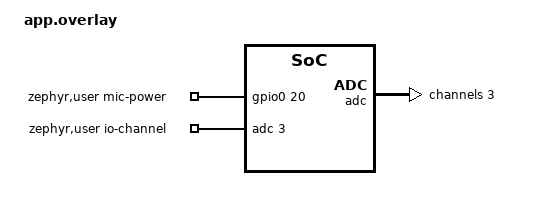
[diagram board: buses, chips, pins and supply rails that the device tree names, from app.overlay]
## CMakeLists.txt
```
# Freestanding Zephyr application: ZEPHYR_BASE must point at the Zephyr repo
# inside ~/zephyrproject.

cmake_minimum_required(VERSION 3.20.0)

find_package(Zephyr REQUIRED HINTS $ENV{ZEPHYR_BASE})
project(microbit_v2_zephyr)

target_sources(app PRIVATE
  src/main.c
  src/accel.c
  src/audio.c
  src/ble.c
  src/buttons.c
  src/display.c
  src/temp.c
)
```

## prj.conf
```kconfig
CONFIG_LOG=y
CONFIG_MAIN_STACK_SIZE=2048

# --- console shell -----------------------------------------------------------
# The board already chooses uart0 for both `zephyr,console` and
# `zephyr,shell-uart`, so the shell lands on the same USB CDC port the log
# already uses. SHELL_LOG_BACKEND is `default y if LOG`, which is what keeps log
# records from shredding a half-typed command line, so it is not set here.
CONFIG_SHELL=y
# Deferred logging moves formatting off the calling thread. The sensor threads
# log from timer and input callbacks, where the synchronous mode's spinlock is
# held across the whole UART write.
CONFIG_LOG_MODE_DEFERRED=y
# `log enable dbg accel` at runtime, which is the point of the per-module
# LOG_MODULE_REGISTER calls -- accel.c, temp.c, and buttons.c all have LOG_DBG
# statements that nothing could otherwise reach without a rebuild.
#
# This only works because every module now registers at LOG_LEVEL_DBG. That
# argument is the COMPILE-TIME ceiling, and log_filter_set() clamps the runtime
# level to it, so with the modules at LOG_LEVEL_INF `log enable dbg accel`
# answered "level set to inf" and silently did nothing.
CONFIG_LOG_CMDS=y
# Raising that ceiling is what makes the console noisy if this line is missing.
# The serial backend's initial limit defaults to LOG_LEVEL_DEFAULT, "the system
# limit", which follows the compile ceiling -- so every module came up at dbg
# and temp.c alone printed a die reading every second. This pins the *initial
# runtime* level to inf. It is not a second ceiling: log_filter_set() clamps
# against the compile-time level, so `log enable dbg accel` still reaches dbg.
CONFIG_SHELL_BACKEND_SERIAL_LOG_LEVEL_INF=y
# `sensor get accel0` and `adc adc@40007000 read 3` reach the LSM303AGR and the
# microphone channel independently of the app's own threads, which is what makes
# them useful for telling a driver fault from an application one.
#
# SENSOR_SHELL is the most expensive line in this file: it `select`s
# SENSOR_ASYNC_API, which pulls in RTIO, and measures at 14 KB of flash and
# 6.6 KB of RAM -- more RAM than the whole rest of the shell tier. Drop it first
# if this ever needs to shrink; ADC_SHELL costs almost nothing by comparison.
CONFIG_SENSOR_SHELL=y
CONFIG_ADC_SHELL=y
# `input report 1 30 1` injects a synthetic button-A press. buttons.c registers
# its callback with INPUT_CALLBACK_DEFINE(NULL, ...), so it listens to every
# device and cannot tell a synthetic event from a real one -- the whole path
# runs, BLE notification included. That is the acoustically clean way to start a
# capture: pressing A physically taps the PCB centimetres from the microphone
# and puts the thump into the very block being measured. `input dump on` logs
# every event, which is the cheapest way to watch the button stream.
CONFIG_INPUT_SHELL=y
CONFIG_INPUT_EVENT_DUMP=y
# KERNEL_SHELL and DEVICE_SHELL are both `default y` once SHELL is on. These two
# are what `kernel thread stacks` needs to report high-water marks, and they are
# only `imply`-ed, so state them: every stack size in this app is a guess until
# it has been measured.
CONFIG_INIT_STACKS=y
CONFIG_THREAD_NAME=y
# `audio raw` and `audio spectrum` print floats. SENSOR_SHELL selects this too,
# but src/audio.c should not depend on that having happened.
CONFIG_CBPRINTF_FP_SUPPORT=y

# --- sensors -----------------------------------------------------------------
# CONFIG_SENSOR is enough: TEMP_NRF5 and LIS2DH are both `default y` off their
# devicetree nodes.
CONFIG_SENSOR=y
# No trigger: the app polls. P0.25 is COMBINED_SENSOR_INT, an open-collector line
# with no pull-up anywhere on the board, and Zephyr's board DTS omits GPIO_PULL_UP,
# so the line can never rise once something has pulled it low. It is also shared
# with the magnetometer and the interface MCU. Selecting NONE drops the driver's
# trigger thread and its 1 KB stack. See accel.c.
CONFIG_LIS2DH_TRIGGER_NONE=y
CONFIG_LIS2DH_ACCEL_RANGE_2G=y
# The magnetometer is unused here, and leaving it out is not just dead weight:
# LIS2MDL is `default y` off the board's DTS and its trigger mode defaults to
# GLOBAL_THREAD, which arms a rising-edge interrupt on that same never-rising
# P0.25 at init, for a sensor nothing reads.
CONFIG_LIS2MDL=n

# --- buttons and buzzer ------------------------------------------------------
CONFIG_GPIO=y
CONFIG_INPUT=y
CONFIG_BUZZER=y

# --- LED matrix --------------------------------------------------------------
# MICROBIT_DISPLAY has no `default y` and depends on DISPLAY + PRINTK.
CONFIG_DISPLAY=y
CONFIG_MICROBIT_DISPLAY=y

# --- audio capture and FFT ---------------------------------------------------
CONFIG_ADC=y
CONFIG_FPU=y
CONFIG_CMSIS_DSP=y
CONFIG_CMSIS_DSP_TRANSFORM=y
CONFIG_CMSIS_DSP_STATISTICS=y
CONFIG_CMSIS_DSP_WINDOW=y

# --- bluetooth ---------------------------------------------------------------
CONFIG_BT=y
CONFIG_BT_PERIPHERAL=y
CONFIG_BT_DEVICE_NAME="microbit-v2"

# The default ATT MTU is 23, which leaves 20 usable bytes -- three accelerometer
# samples. Raising it is what makes the batching requirement mean anything.
CONFIG_BT_L2CAP_TX_MTU=247
CONFIG_BT_BUF_ACL_TX_SIZE=251
CONFIG_BT_BUF_ACL_RX_SIZE=251
CONFIG_BT_CTLR_DATA_LENGTH_MAX=251

# No CONFIG_BT_GATT_CLIENT: this is a pure GATT server. It was set so the
# peripheral could call bt_gatt_exchange_mtu() itself, which turned out to hang
# the ATT transaction against BlueZ and drop the link 30 s later. See ble.c.

# Ask for a short connection interval: 6 * 1.25 ms = 7.5 ms to 12 * 1.25 = 15 ms.
CONFIG_BT_PERIPHERAL_PREF_MIN_INT=6
CONFIG_BT_PERIPHERAL_PREF_MAX_INT=12
CONFIG_BT_PERIPHERAL_PREF_LATENCY=0
CONFIG_BT_PERIPHERAL_PREF_TIMEOUT=400
```

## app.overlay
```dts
/*
 * The micro:bit V2's microphone is an ANALOG MEMS part. Zephyr's board files
 * describe it not at all, so everything about it lives here:
 *
 *   - signal out -> P0.05 = AIN3
 *   - enable/LED -> P0.20
 *
 * These pin numbers come from the micro:bit hardware documentation, not from
 * Zephyr. The SoC dtsi leaves `adc` disabled, so we enable it too.
 */

/ {
	zephyr,user {
		io-channels = <&adc 3>;
		mic-power-gpios = <&gpio0 20 GPIO_ACTIVE_HIGH>;
	};
};

&adc {
	status = "okay";
	#address-cells = <1>;
	#size-cells = <0>;

	channel@3 {
		reg = <3>;
		/* Full scale is 0.6 V / 4 = 150 mV, which is chosen for the
		 * microphone rather than for safety. The obvious setting --
		 * ADC_GAIN_1_4 against ADC_REF_VDD_1_4, full scale VDD -- put
		 * the whole signal in the bottom 2 % of the range, where what
		 * the FFT mostly saw was the ADC's own quantisation: a 1 kHz
		 * tone stood 4.0 dB clear of the noise floor there against
		 * 18.6 dB here. The microphone idles near 69 mV, so 150 mV
		 * leaves the bias at about 46 % of range with ~29 dB of
		 * headroom before clipping -- watch `audio raw`'s "at rails"
		 * counter if a loud source is ever held against the board.
		 * Measured; see README.md, "known limitations".
		 */
		zephyr,gain = "ADC_GAIN_4";
		zephyr,reference = "ADC_REF_INTERNAL";
		/* The reference itself, 0.6 V -- not the full-scale input.
		 * adc_raw_to_millivolts() multiplies by this and then inverts
		 * the x4 gain, which lands full scale at 150 mV. Nothing in the
		 * capture path reads it, but without it
		 * `adc_raw_to_millivolts_dt()` silently converts everything to
		 * 0 mV: adc_dt_spec fills vref_mv with DT_PROP_OR(..., 0), so
		 * the omission costs a wrong answer rather than a build error.
		 * `audio raw` and the `adc` shell command are the users.
		 */
		zephyr,vref-mv = <600>;
		zephyr,acquisition-time = <ADC_ACQ_TIME(ADC_ACQ_TIME_MICROSECONDS, 3)>;
		zephyr,input-positive = <NRF_SAADC_AIN3>;	/* P0.05 */
		zephyr,resolution = <12>;
	};
};
```

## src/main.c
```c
/*
 * See README.md for the requirements this implements and for the hardware
 * notes -- in particular, why the microphone goes through the SAADC.
 */

#include "accel.h"
#include "audio.h"
#include "ble.h"
#include "buttons.h"
#include "display.h"
#include "temp.h"

#include <zephyr/kernel.h>
#include <zephyr/logging/log.h>

LOG_MODULE_REGISTER(main, LOG_LEVEL_DBG);

/* How often to report queue health on the console. */
#define STATS_PERIOD_MS 10000

int main(void)
{
	int err;

	LOG_INF("micro:bit V2 sensor application starting");

	err = display_init();
	if (err) {
		return err;
	}

	err = buttons_init();
	if (err) {
		return err;
	}

	err = audio_start();
	if (err) {
		return err;
	}

	err = ble_start();
	if (err) {
		return err;
	}

	err = accel_start();
	if (err) {
		return err;
	}

	err = temp_start();
	if (err) {
		return err;
	}

	display_text("hi");

	for (;;) {
		k_sleep(K_MSEC(STATS_PERIOD_MS));
		LOG_INF("accel queue %u/%u, dropped %u, overruns %u",
			k_msgq_num_used_get(&accel_msgq),
			k_msgq_num_free_get(&accel_msgq) + k_msgq_num_used_get(&accel_msgq),
			accel_dropped(), accel_overruns());
	}

	return 0;
}
```

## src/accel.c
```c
/*
 * LSM303AGR accelerometer at 100 Hz.
 *
 * This polls on a kernel timer rather than using the chip's data-ready
 * interrupt. The board makes the trigger unusable as Zephyr describes it, but
 * not for the reason the polarity of the pin suggests.
 *
 * On the V2 schematic the sensor's INT1_XL drives the base of T7, a DTC143E
 * digital NPN, whose collector is COMBINED_SENSOR_INT on P0.25. (The
 * magnetometer's DRDY drives T5 onto the same net, as does the interface MCU.)
 * That common-emitter stage inverts, so the chip's default ACTIVE-HIGH INT1 is
 * already the right polarity here -- the board is what makes the line
 * active-low and open-collector, and the LSM303AGR's own polarity bit should be
 * left alone.
 *
 * What is missing is a pull-up. Nothing on the board pulls this net high, and
 * Zephyr's board DTS declares irq-gpios without GPIO_PULL_UP, so lis2dh's bare
 * gpio_pin_configure_dt(..., GPIO_INPUT) leaves the pin floating. The first
 * data-ready pulls it to 0 V, the read releases T7, and the floating input just
 * stays there: measured, P0.25 sits low forever and no further edge occurs.
 * Polarity is provably not the blocker -- int1-gpio-config defaults to
 * EDGE_BOTH, which would have caught an edge in either direction.
 *
 * An overlay setting GPIO_PULL_UP on the accel's irq-gpios (plus
 * int1-gpio-config = LEVEL_LOW) would make the trigger work. Polling is kept
 * anyway because the line is shared: the interface MCU can assert it while the
 * accelerometer is idle, and hold it low across our own edges. A 6-byte burst
 * at 100 Hz is ~2 % of a 400 kHz I2C bus. See README.md, "known limitations".
 */

#include "accel.h"

#include <zephyr/device.h>
#include <zephyr/drivers/sensor.h>
#include <zephyr/logging/log.h>

LOG_MODULE_REGISTER(accel, LOG_LEVEL_DBG);

#define ACCEL_SAMPLE_RATE_HZ 100
#define ACCEL_PERIOD_MS      (1000 / ACCEL_SAMPLE_RATE_HZ)

/* One second of headroom. The BLE thread drains far faster than this when a
 * central is subscribed; the depth only matters while nobody is listening.
 */
#define ACCEL_QUEUE_DEPTH 128

#define ACCEL_STACK_SIZE 1024
#define ACCEL_PRIORITY   5

K_MSGQ_DEFINE(accel_msgq, sizeof(struct accel_sample), ACCEL_QUEUE_DEPTH, 4);

static const struct device *const accel_dev = DEVICE_DT_GET(DT_ALIAS(accel0));
static K_TIMER_DEFINE(accel_timer, NULL, NULL);
static uint32_t dropped;
static uint32_t overruns;

/* The sensor API reports m/s^2. Convert via micro-m/s^2 so the whole thing stays
 * in integer arithmetic: 1 g = 9.80665 m/s^2.
 */
static int16_t to_milli_g(const struct sensor_value *val)
{
	int64_t micro_m_s2 = sensor_value_to_micro(val);

	return (int16_t)CLAMP((micro_m_s2 * 1000) / 9806650, INT16_MIN, INT16_MAX);
}

static void sample_once(void)
{
	struct sensor_value val[3];
	struct accel_sample sample;
	int err;

	err = sensor_sample_fetch_chan(accel_dev, SENSOR_CHAN_ACCEL_XYZ);
	if (err == -ENODATA) {
		/* The chip had no new sample: its data-ready bit was still clear. Normal
		 * for a poller -- it happens on the first read after the ODR change, and
		 * whenever our 10 ms tick drifts just ahead of the sensor's own clock.
		 */
		LOG_DBG("no new sample");
		return;
	}
	if (err) {
		LOG_ERR("fetch failed (%d)", err);
		return;
	}

	err = sensor_channel_get(accel_dev, SENSOR_CHAN_ACCEL_XYZ, val);
	if (err) {
		LOG_ERR("channel get failed (%d)", err);
		return;
	}

	sample.t_ms = k_uptime_get_32();
	sample.x = to_milli_g(&val[0]);
	sample.y = to_milli_g(&val[1]);
	sample.z = to_milli_g(&val[2]);

	/* Drop the oldest sample rather than the newest: a stalled consumer should
	 * cost us history, not the live signal.
	 */
	if (k_msgq_put(&accel_msgq, &sample, K_NO_WAIT) != 0) {
		struct accel_sample discard;

		(void)k_msgq_get(&accel_msgq, &discard, K_NO_WAIT);
		(void)k_msgq_put(&accel_msgq, &sample, K_NO_WAIT);
		dropped++;
	}
}

static void accel_thread(void *p1, void *p2, void *p3)
{
	ARG_UNUSED(p1);
	ARG_UNUSED(p2);
	ARG_UNUSED(p3);

	k_timer_start(&accel_timer, K_MSEC(ACCEL_PERIOD_MS), K_MSEC(ACCEL_PERIOD_MS));

	for (;;) {
		/* Counts every expiry, so the period stays anchored to the timer
		 * instead of drifting by however long each read takes.
		 */
		uint32_t ticks = k_timer_status_sync(&accel_timer);

		if (ticks > 1) {
			overruns += ticks - 1;
		}

		sample_once();
	}
}

K_THREAD_DEFINE(accel_tid, ACCEL_STACK_SIZE, accel_thread, NULL, NULL, NULL, ACCEL_PRIORITY, 0,
		K_TICKS_FOREVER);

int accel_start(void)
{
	struct sensor_value odr = {.val1 = ACCEL_SAMPLE_RATE_HZ, .val2 = 0};
	int err;

	if (!device_is_ready(accel_dev)) {
		LOG_ERR("%s not ready", accel_dev->name);
		return -ENODEV;
	}

	/* Match the chip's output rate to the poll rate, so each read returns a
	 * fresh sample rather than repeating one.
	 */
	err = sensor_attr_set(accel_dev, SENSOR_CHAN_ACCEL_XYZ, SENSOR_ATTR_SAMPLING_FREQUENCY,
			      &odr);
	if (err) {
		LOG_ERR("cannot set %d Hz ODR (%d)", ACCEL_SAMPLE_RATE_HZ, err);
		return err;
	}

	k_thread_start(accel_tid);
	LOG_INF("accelerometer polling at %d Hz", ACCEL_SAMPLE_RATE_HZ);
	return 0;
}

uint32_t accel_dropped(void)
{
	return dropped;
}

uint32_t accel_overruns(void)
{
	return overruns;
}
```

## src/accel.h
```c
#ifndef APP_ACCEL_H_
#define APP_ACCEL_H_

#include <stdint.h>
#include <zephyr/kernel.h>

/** One accelerometer sample. Axes are milli-g. */
struct accel_sample {
	uint32_t t_ms;
	int16_t x;
	int16_t y;
	int16_t z;
};

/** Pending samples, filled by the sampling thread, drained by the BLE thread. */
extern struct k_msgq accel_msgq;

/** Start the 100 Hz sampling thread. */
int accel_start(void);

/** Samples dropped since boot because the queue was full. */
uint32_t accel_dropped(void);

/** Sampling periods missed since boot because a read overran its 10 ms slot. */
uint32_t accel_overruns(void);

#endif /* APP_ACCEL_H_ */
```

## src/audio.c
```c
/*
 * Audio capture and peak-frequency detection.
 *
 * The micro:bit V2's microphone is an ANALOG MEMS part on AIN3, so this goes
 * through the SAADC, not the PDM peripheral. Three conditions have to hold for
 * the SAADC's hardware sample timer to engage (see start_read() in
 * drivers/adc/adc_nrfx_saadc.c): exactly one active channel, a NULL sequence
 * callback, and interval_us <= 128. Miss any of them and the driver quietly
 * falls back to software-timed sampling, which cannot hold this rate.
 *
 * One second of audio is 61 KB, so capture is block-wise: one 2048-sample read,
 * one FFT, accumulate, discard, repeat. Averaging the 15 spectra (Welch's
 * method) is what pulls a tone out of the noise floor.
 */

#include "audio.h"
#include "display.h"

#include <arm_math.h>

#include <float.h>
#include <math.h>
#include <string.h>

#include <zephyr/devicetree.h>
#include <zephyr/drivers/adc.h>
#include <zephyr/drivers/clock_control.h>
#include <zephyr/drivers/clock_control/nrf_clock_control.h>
#include <zephyr/drivers/gpio.h>
#include <zephyr/kernel.h>
#include <zephyr/logging/log.h>

#ifdef CONFIG_SHELL
#include <zephyr/shell/shell.h>
#include <zephyr/shell/shell_string_conv.h>
#endif

LOG_MODULE_REGISTER(audio, LOG_LEVEL_DBG);

#define FFT_SIZE 2048
#define FFT_BINS (FFT_SIZE / 2)

/* interval_us is an integer, and 32 us is the closest step to 32 kHz. It does
 * NOT give 1000000/32 = 31250 Hz, which is what this used to assume.
 *
 * Zephyr programs the SAADC's sample timer through interval_to_cc()
 * (drivers/adc/adc_nrfx_saadc.c:503), which returns interval_us * 16 - 1, so
 * 32 us asks for CC = 511 rather than 512. The nRF52833 then samples at
 * 16 MHz / CC. The difference is only 0.2 %, but it is a systematic bias on
 * every frequency this reports, so it is worth deriving rather than assuming --
 * measured against a tone on a known bin centre, see README.md.
 *
 * These three must move together: SAMPLE_INTERVAL_US is the only real knob.
 */
#define SAMPLE_INTERVAL_US 32
#define SAMPLE_RATE_CC     (SAMPLE_INTERVAL_US * 16 - 1) /* 511 */
#define SAMPLE_RATE_HZ     (16000000 / SAMPLE_RATE_CC)   /* 31311 */

/* 15 * 2048 / 31311 = 0.98 s. */
#define BLOCK_COUNT 15

/* Time for the microphone bias to settle after power is applied. */
#define MIC_SETTLE_MS 10

/* What a capture should take if the SAADC's hardware sample timer engaged. The
 * FFTs run between adc_read() calls, so the real figure sits a few per cent
 * above this; several times this means the driver fell back to software timing.
 */
#define CAPTURE_EXPECTED_MS ((BLOCK_COUNT * FFT_SIZE * 1000U) / SAMPLE_RATE_HZ + MIC_SETTLE_MS)

/* Ignore DC and the bins below roughly 30 Hz. Bin width is 15.29 Hz. */
#define MIN_BIN 2

#define AUDIO_STACK_SIZE 2048
#define AUDIO_PRIORITY   6

static const struct adc_dt_spec mic_adc = ADC_DT_SPEC_GET(DT_PATH(zephyr_user));
static const struct gpio_dt_spec mic_power =
	GPIO_DT_SPEC_GET(DT_PATH(zephyr_user), mic_power_gpios);

/* The SAADC's SAMPLERATE.CC timer counts PCLK16M, which derives from HFCLK --
 * and HFCLK runs from the internal RC oscillator unless something asks for the
 * crystal. The BLE controller asks around each radio event
 * (z_nrf_clock_bt_ctlr_hf_request) and drops it again, so without this a capture
 * is stitched together from crystal-accurate and RC-accurate stretches and the
 * reported frequency lands about 0.5 % low.
 *
 * Held on by default, for the roughly one second a capture lasts. That is a real
 * cost -- the crystal draws more than the RC -- but captures are user-triggered
 * and infrequent, and BLE is starting the same crystal every few tens of
 * milliseconds anyway. `audio hfxo off` turns it back off, which is how the
 * measurement in README.md was made.
 *
 * Take it with the reference-counted request API and NOT with
 * clock_control_on()/clock_control_off(). The two are not interchangeable here:
 * clock_control_nrf_common.c tags the clock with the context that started it,
 * COMMON_CTX_API for clock_control_on() against COMMON_CTX_ONOFF for a request,
 * and set_starting_state() fails with -EPERM when a second context asks while
 * the first holds it. The nRF die-temperature driver takes HFCLK through the
 * request API for every conversion (temp_nrf5_sample_fetch, which triggers the
 * TEMP START task from the request's completion callback), so with
 * clock_control_on() the once-a-second fetch that landed inside a capture got
 * -EPERM, and that failed transition leaves the onoff manager latched in its
 * error state for good: every later request returns -EIO without ever notifying,
 * and the driver's k_sem_take(&data->device_sync_sem, K_FOREVER) never returns.
 * One capture was enough to hang the temperature thread until the next reset --
 * the die-temperature BLE stream simply stopped. The request API shares the
 * clock instead of seizing it, which is what both users need.
 */
static const struct device *const hfclk = DEVICE_DT_GET_ONE(nordic_nrf_clock_hfclk);
static atomic_t hfxo_hold = ATOMIC_INIT(1);

/* The crystal's own startup_time_us is 360, so this is only a deadlock guard. */
#define HFXO_START_TIMEOUT_MS 10

static int16_t raw[FFT_SIZE];
static float32_t fft_in[FFT_SIZE];
static float32_t fft_out[FFT_SIZE];
static float32_t window[FFT_SIZE];
static float32_t mag_avg[FFT_BINS];

static arm_rfft_fast_instance_f32 fft;

static K_SEM_DEFINE(capture_req, 0, 1);
static atomic_t capture_active;

/* Enough of the last capture to describe it on the shell. raw[] and mag_avg[]
 * survive between captures precisely so they can be inspected afterwards; these
 * say which capture they belong to and whether it ran at the right rate.
 */
static uint32_t capture_count;
static uint32_t capture_ms;

void audio_request_capture(void)
{
	if (atomic_get(&capture_active)) {
		return;
	}

	k_sem_give(&capture_req);
}

bool audio_capture_active(void)
{
	return atomic_get(&capture_active) != 0;
}

/* One 2048-sample block into raw[]. */
static int capture_block(void)
{
	static const struct adc_sequence_options opts = {
		.interval_us = SAMPLE_INTERVAL_US,
		.extra_samplings = FFT_SIZE - 1,
		/* Must stay NULL: a callback forces software-timed sampling. */
		.callback = NULL,
	};
	struct adc_sequence seq = {
		.options = &opts,
		.buffer = raw,
		.buffer_size = sizeof(raw),
	};
	int err;

	err = adc_sequence_init_dt(&mic_adc, &seq);
	if (err) {
		return err;
	}

	return adc_read_dt(&mic_adc, &seq);
}

/* Convert, remove DC, window, transform, and fold the magnitude spectrum into
 * the running average.
 */
static void accumulate_block(void)
{
	float32_t mean;

	for (size_t i = 0; i < FFT_SIZE; i++) {
		fft_in[i] = (float32_t)raw[i];
	}

	arm_mean_f32(fft_in, FFT_SIZE, &mean);
	arm_offset_f32(fft_in, -mean, fft_in, FFT_SIZE);
	arm_mult_f32(fft_in, window, fft_in, FFT_SIZE);

	/* Destroys fft_in, which is why the conversion above rebuilds it. */
	arm_rfft_fast_f32(&fft, fft_in, fft_out, 0);

	/* arm_rfft_fast_f32 packs DC in [0] and Nyquist in [1], then interleaved
	 * complex pairs. So bin k, for k >= 1, starts at fft_out[2k].
	 */
	mag_avg[0] += fabsf(fft_out[0]);
	for (size_t k = 1; k < FFT_BINS; k++) {
		float32_t re = fft_out[2 * k];
		float32_t im = fft_out[2 * k + 1];

		mag_avg[k] += sqrtf(re * re + im * im);
	}
}

/* Centre frequency of bin k. Takes a float because the peak is interpolated to
 * a fractional bin; bin_hz(1.0f) is the bin width.
 */
static float32_t bin_hz(float32_t k)
{
	return k * (float32_t)SAMPLE_RATE_HZ / (float32_t)FFT_SIZE;
}

/* Peak bin, refined by fitting a parabola through the log-magnitudes of the
 * peak and its two neighbours. Raw bin width is 15.29 Hz; this gets well inside
 * that. Returns Hz, or 0 if the spectrum has no usable peak.
 */
static float32_t peak_frequency(void)
{
	float32_t best = 0.0f;
	uint32_t peak = 0;
	float32_t a, b, c, denom, delta;

	for (uint32_t k = MIN_BIN; k < FFT_BINS - 1; k++) {
		if (mag_avg[k] > best) {
			best = mag_avg[k];
			peak = k;
		}
	}

	if (peak == 0 || best <= 0.0f) {
		return 0.0f;
	}

	a = logf(mag_avg[peak - 1] + FLT_MIN);
	b = logf(mag_avg[peak] + FLT_MIN);
	c = logf(mag_avg[peak + 1] + FLT_MIN);

	denom = a - 2.0f * b + c;
	delta = (denom != 0.0f) ? (0.5f * (a - c) / denom) : 0.0f;

	/* A parabola fitted to a genuine peak puts the vertex inside the bin. */
	if (delta < -0.5f || delta > 0.5f) {
		delta = 0.0f;
	}

	return bin_hz((float32_t)peak + delta);
}

static void run_capture(void)
{
	float32_t hz;
	uint32_t started;
	bool hold;
	int err;

	memset(mag_avg, 0, sizeof(mag_avg));

	/* Taken before the clock is read, so the crystal's ramp-up does not land
	 * in the elapsed figure the sample-rate check depends on.
	 */
	hold = atomic_get(&hfxo_hold) != 0;
	if (hold) {
		err = nrf_clock_control_request_sync(hfclk, NULL, K_MSEC(HFXO_START_TIMEOUT_MS));
		if (err) {
			LOG_WRN("cannot hold HFXO (%d)", err);
			hold = false;
		}
	}

	started = k_uptime_get_32();

	err = gpio_pin_set_dt(&mic_power, 1);
	if (err) {
		LOG_ERR("cannot power the microphone (%d)", err);
		goto release;
	}
	k_sleep(K_MSEC(MIC_SETTLE_MS));

	for (int i = 0; i < BLOCK_COUNT; i++) {
		err = capture_block();
		if (err) {
			LOG_ERR("block %d failed (%d)", i, err);
			(void)gpio_pin_set_dt(&mic_power, 0);
			goto release;
		}
		accumulate_block();
	}

	(void)gpio_pin_set_dt(&mic_power, 0);
	if (hold) {
		(void)nrf_clock_control_release(hfclk, NULL);
		hold = false;
	}

	/* Sanity check on the sample clock. The SAADC silently falls back to
	 * software-timed sampling if any precondition slips, so a capture that
	 * takes much longer than BLOCK_COUNT * FFT_SIZE / SAMPLE_RATE_HZ means the
	 * hardware timer did not engage and the reported frequency is wrong.
	 */
	capture_ms = k_uptime_get_32() - started;
	capture_count++;
	LOG_INF("capture #%u took %u ms (expected ~%u)", capture_count, capture_ms,
		CAPTURE_EXPECTED_MS);

	hz = peak_frequency();
	if (hz <= 0.0f) {
		LOG_WRN("no peak found");
		display_text("?");
		return;
	}

	LOG_INF("peak frequency %u Hz", (uint32_t)(hz + 0.5f));
	display_frequency((uint32_t)(hz + 0.5f));
	return;

release:
	if (hold) {
		(void)nrf_clock_control_release(hfclk, NULL);
	}
}

static void audio_thread(void *p1, void *p2, void *p3)
{
	ARG_UNUSED(p1);
	ARG_UNUSED(p2);
	ARG_UNUSED(p3);

	for (;;) {
		k_sem_take(&capture_req, K_FOREVER);

		atomic_set(&capture_active, 1);
		run_capture();
		atomic_set(&capture_active, 0);
	}
}

K_THREAD_DEFINE(audio_tid, AUDIO_STACK_SIZE, audio_thread, NULL, NULL, NULL, AUDIO_PRIORITY, 0,
		K_TICKS_FOREVER);

int audio_start(void)
{
	int err;

	if (!adc_is_ready_dt(&mic_adc)) {
		LOG_ERR("ADC not ready");
		return -ENODEV;
	}

	if (!gpio_is_ready_dt(&mic_power)) {
		LOG_ERR("microphone power GPIO not ready");
		return -ENODEV;
	}

	if (!device_is_ready(hfclk)) {
		LOG_ERR("HFCLK not ready");
		return -ENODEV;
	}

	err = gpio_pin_configure_dt(&mic_power, GPIO_OUTPUT_INACTIVE);
	if (err) {
		LOG_ERR("cannot configure microphone power (%d)", err);
		return err;
	}

	err = adc_channel_setup_dt(&mic_adc);
	if (err) {
		LOG_ERR("cannot set up ADC channel (%d)", err);
		return err;
	}

	/* Use the size-specific initialiser: arm_rfft_fast_init_f32() dispatches
	 * on length and drags every twiddle table from 32 to 4096 into flash.
	 */
	if (arm_rfft_fast_init_2048_f32(&fft) != ARM_MATH_SUCCESS) {
		LOG_ERR("FFT init failed");
		return -EINVAL;
	}

	arm_hanning_f32(window, FFT_SIZE);

	k_thread_start(audio_tid);
	LOG_INF("audio ready: %d Hz, %d x %d-point FFT", SAMPLE_RATE_HZ, BLOCK_COUNT, FFT_SIZE);
	return 0;
}

#ifdef CONFIG_SHELL

/* Shell diagnostics for the capture path.
 *
 * The pipeline is otherwise write-only: accumulate_block() builds a 1024-bin
 * averaged spectrum and peak_frequency() collapses it to the single number that
 * reaches the LED matrix. When that number is wrong, the spectrum and the last
 * raw block are what say why -- a harmonic picked over the fundamental, a
 * clipped or unpowered microphone, a sample clock that fell back to software
 * timing. Both buffers are static and outlive the capture, so these commands
 * only have to read them.
 *
 * Both refuse to read while the audio thread is mid-capture, which is the only
 * writer. The check is a plain load rather than a lock: these are human-driven
 * commands and the alternative -- holding a mutex across a one-second capture --
 * buys nothing here.
 */

#define SPECTRUM_ROWS_DEFAULT 8
#define SPECTRUM_ROWS_MAX     32

/* Common preamble: refuse unless there is a settled capture to describe. */
static int check_capture(const struct shell *sh)
{
	if (atomic_get(&capture_active)) {
		shell_warn(sh, "capture in progress, try again in a second");
		return -EBUSY;
	}

	if (capture_count == 0) {
		shell_warn(sh, "no capture yet -- press button A");
		return -ENODATA;
	}

	return 0;
}

/* Statistics over the last 2048-sample block, in ADC counts and in millivolts.
 *
 * The channel is single-ended with ADC_GAIN_4 against ADC_REF_INTERNAL, so
 * full scale is 150 mV across the 12-bit range and a healthy analog microphone
 * idles around 46 % of range. A mean near zero means mic-power-gpios never
 * asserted; samples resting on either rail mean the signal is clipping.
 */
static int cmd_audio_raw(const struct shell *sh, size_t argc, char **argv)
{
	const int32_t full_scale = BIT(mic_adc.resolution) - 1;
	int32_t min = INT32_MAX;
	int32_t max = INT32_MIN;
	int64_t sum = 0;
	uint32_t at_low = 0;
	uint32_t at_high = 0;
	float32_t mean, sq = 0.0f, rms;
	int32_t mean_mv, pp_mv;
	int err;

	ARG_UNUSED(argc);
	ARG_UNUSED(argv);

	err = check_capture(sh);
	if (err) {
		return err;
	}

	for (size_t i = 0; i < FFT_SIZE; i++) {
		int32_t v = raw[i];

		min = MIN(min, v);
		max = MAX(max, v);
		sum += v;
		at_low += (v <= 0);
		at_high += (v >= full_scale);
	}

	mean = (float32_t)sum / (float32_t)FFT_SIZE;

	/* AC RMS: the DC bias is most of the signal, and it is what
	 * accumulate_block() subtracts before windowing.
	 */
	for (size_t i = 0; i < FFT_SIZE; i++) {
		float32_t d = (float32_t)raw[i] - mean;

		sq += d * d;
	}
	rms = sqrtf(sq / (float32_t)FFT_SIZE);

	/* adc_raw_to_millivolts_dt() converts in place and applies the gain,
	 * reference, and resolution from the devicetree channel -- the values
	 * app.overlay compiled in, not whatever the channel is set to now. The
	 * `adc` shell command reconfigures this same channel, so after using it
	 * to retune the gain, the counts here stay true and the millivolts do
	 * not. See README.md.
	 */
	mean_mv = (int32_t)(mean + 0.5f);
	pp_mv = max - min;
	if (adc_raw_to_millivolts_dt(&mic_adc, &mean_mv) != 0 ||
	    adc_raw_to_millivolts_dt(&mic_adc, &pp_mv) != 0) {
		mean_mv = -1;
		pp_mv = -1;
	}

	shell_print(sh, "capture #%u, block %d of %d, %u ms elapsed (expected ~%u)", capture_count,
		    BLOCK_COUNT, BLOCK_COUNT, capture_ms, CAPTURE_EXPECTED_MS);
	shell_print(sh, "%d samples at %d Hz, full scale %d counts", FFT_SIZE, SAMPLE_RATE_HZ,
		    full_scale);
	shell_print(sh, "  min %6d   max %6d   peak-to-peak %6d (%d mV)", min, max, max - min,
		    pp_mv);
	shell_print(sh, "  mean %11.1f counts (%d mV)   ac rms %.1f counts", (double)mean, mean_mv,
		    (double)rms);
	shell_print(sh, "  at rails: %u low, %u high", at_low, at_high);

	return 0;
}

/* The loudest bins of the averaged spectrum, strongest first.
 *
 * Rows are selected by repeated scan rather than by sorting mag_avg[]: the
 * array is 1024 floats that the next capture wants intact, and at most 32 rows
 * a scan apiece is far cheaper than a copy. Ordering is on (magnitude, bin) so
 * that bins of exactly equal magnitude still emerge one per row instead of the
 * lowest one repeating.
 */
static int cmd_audio_spectrum(const struct shell *sh, size_t argc, char **argv)
{
	uint32_t rows = SPECTRUM_ROWS_DEFAULT;
	float32_t prev_mag = FLT_MAX;
	uint32_t prev_bin = 0;
	float32_t top = 0.0f;
	float32_t floor_mag;
	int err;

	if (argc == 2) {
		/* shell_strtol() writes *err only when the conversion fails, so
		 * this has to start at 0 -- left uninitialised it rejects every
		 * valid argument on whatever the stack happened to hold.
		 */
		long n;

		err = 0;
		n = shell_strtol(argv[1], 10, &err);

		if (err != 0 || n < 1 || n > SPECTRUM_ROWS_MAX) {
			shell_error(sh, "rows must be 1..%d", SPECTRUM_ROWS_MAX);
			return -EINVAL;
		}
		rows = (uint32_t)n;
	}

	err = check_capture(sh);
	if (err) {
		return err;
	}

	/* Over the same bins peak_frequency() searches, so the ratio between a
	 * row and this is what says whether a peak stands out at all.
	 */
	arm_mean_f32(&mag_avg[MIN_BIN], FFT_BINS - MIN_BIN, &floor_mag);

	shell_print(sh, "capture #%u, %d blocks averaged, %u ms elapsed (expected ~%u)",
		    capture_count, BLOCK_COUNT, capture_ms, CAPTURE_EXPECTED_MS);
	shell_print(sh, "%d-point fft at %d Hz, bin width %.2f Hz, bins %d..%d searched", FFT_SIZE,
		    SAMPLE_RATE_HZ, (double)bin_hz(1.0f), MIN_BIN, FFT_BINS - 2);
	shell_print(sh, "interpolated peak %.2f Hz, mean magnitude %.1f", (double)peak_frequency(),
		    (double)floor_mag);
	shell_print(sh, " rank   bin        Hz     magnitude      dBc");

	for (uint32_t r = 0; r < rows; r++) {
		float32_t best = 0.0f;
		uint32_t best_bin = 0;
		bool found = false;

		for (uint32_t k = MIN_BIN; k < FFT_BINS; k++) {
			float32_t m = mag_avg[k];

			/* Strictly after the previous row in (magnitude, bin)
			 * order -- everything already printed, skipped.
			 */
			if (m > prev_mag || (m == prev_mag && k <= prev_bin)) {
				continue;
			}
			if (!found || m > best || (m == best && k < best_bin)) {
				best = m;
				best_bin = k;
				found = true;
			}
		}

		if (!found) {
			break;
		}
		if (r == 0) {
			top = best;
		}

		/* dBc, relative to the strongest bin, so row 1 is always 0.0.
		 * FLT_MIN keeps log10f off zero on a silent spectrum.
		 */
		shell_print(sh, " %4u  %4u  %8.2f  %12.1f  %7.1f", r + 1, best_bin,
			    (double)bin_hz((float32_t)best_bin), (double)best,
			    (double)(20.0f * log10f((best + FLT_MIN) / (top + FLT_MIN))));

		prev_mag = best;
		prev_bin = best_bin;
	}

	return 0;
}

/* Turn the crystal hold off or back on, or report it.
 *
 * The hold is on by default, so this is mostly a way to get the old behaviour
 * back: measuring the sample rate both ways on one board, in one room, with no
 * reflash in between to argue about.
 */
static int cmd_audio_hfxo(const struct shell *sh, size_t argc, char **argv)
{
	if (argc == 2) {
		if (strcmp(argv[1], "on") == 0) {
			atomic_set(&hfxo_hold, 1);
		} else if (strcmp(argv[1], "off") == 0) {
			atomic_set(&hfxo_hold, 0);
		} else {
			shell_error(sh, "expected on or off");
			return -EINVAL;
		}
	}

	/* The status is whatever is true at this instant, and with BLE
	 * advertising "running" is perfectly possible even with the hold off --
	 * the controller takes the crystal for each radio event.
	 */
	shell_print(sh, "hfxo hold %s, hfclk %s right now", atomic_get(&hfxo_hold) ? "on" : "off",
		    clock_control_get_status(hfclk, NULL) == CLOCK_CONTROL_STATUS_ON ? "running"
										     : "stopped");
	return 0;
}

SHELL_STATIC_SUBCMD_SET_CREATE(
	sub_audio,
	SHELL_CMD_ARG(hfxo, NULL,
		      "Hold the HF crystal on across a capture (default on).\n"
		      "Usage: audio hfxo [on|off]   (no argument reports)",
		      cmd_audio_hfxo, 1, 1),
	SHELL_CMD_ARG(raw, NULL,
		      "Statistics over the last captured block.\n"
		      "Usage: audio raw",
		      cmd_audio_raw, 1, 0),
	SHELL_CMD_ARG(spectrum, NULL,
		      "Loudest bins of the last averaged spectrum.\n"
		      "Usage: audio spectrum [rows]   (default 8, max 32)",
		      cmd_audio_spectrum, 1, 1),
	SHELL_SUBCMD_SET_END);

SHELL_CMD_REGISTER(audio, &sub_audio, "Audio capture diagnostics", NULL);

#endif /* CONFIG_SHELL */
```

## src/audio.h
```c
#ifndef APP_AUDIO_H_
#define APP_AUDIO_H_

#include <stdbool.h>

/** Check the ADC channel and start the capture thread. */
int audio_start(void);

/** Ask for a capture. Ignored if one is already running. */
void audio_request_capture(void);

/** True from the moment a capture is accepted until its result is displayed. */
bool audio_capture_active(void);

#endif /* APP_AUDIO_H_ */
```

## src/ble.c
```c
/*
 * One custom service with three notify characteristics. The accelerometer
 * stream is batched: the batch size is derived from the negotiated ATT MTU, so
 * each notification fills as much of a connection interval as the link allows.
 */

#include "ble.h"
#include "accel.h"

#include <zephyr/bluetooth/bluetooth.h>
#include <zephyr/bluetooth/conn.h>
#include <zephyr/bluetooth/gatt.h>
#include <zephyr/bluetooth/uuid.h>
#include <zephyr/kernel.h>
#include <zephyr/logging/log.h>
#include <zephyr/sys/byteorder.h>

LOG_MODULE_REGISTER(ble, LOG_LEVEL_DBG);

/* f1b7 0001..0004 -9c4e-4a1d-9a6b-2f0c1d4e7a30 */
#define UUID_SERVICE_VAL BT_UUID_128_ENCODE(0xf1b70001, 0x9c4e, 0x4a1d, 0x9a6b, 0x2f0c1d4e7a30)
#define UUID_ACCEL_VAL   BT_UUID_128_ENCODE(0xf1b70002, 0x9c4e, 0x4a1d, 0x9a6b, 0x2f0c1d4e7a30)
#define UUID_TEMP_VAL    BT_UUID_128_ENCODE(0xf1b70003, 0x9c4e, 0x4a1d, 0x9a6b, 0x2f0c1d4e7a30)
#define UUID_BUTTON_VAL  BT_UUID_128_ENCODE(0xf1b70004, 0x9c4e, 0x4a1d, 0x9a6b, 0x2f0c1d4e7a30)

static const struct bt_uuid_128 uuid_service = BT_UUID_INIT_128(UUID_SERVICE_VAL);
static const struct bt_uuid_128 uuid_accel = BT_UUID_INIT_128(UUID_ACCEL_VAL);
static const struct bt_uuid_128 uuid_temp = BT_UUID_INIT_128(UUID_TEMP_VAL);
static const struct bt_uuid_128 uuid_button = BT_UUID_INIT_128(UUID_BUTTON_VAL);

/* Accelerometer payload: uint32 t_ms, uint8 count, then count * {int16 x,y,z}. */
#define ACCEL_HDR_LEN    5
#define ACCEL_SAMPLE_LEN 6

/* Cap the batch so latency stays bounded at 100 ms even when the MTU would
 * allow far more. At 247 the MTU alone would permit 39 samples -- 390 ms.
 */
#define ACCEL_MAX_BATCH 10

/* How long to keep waiting for the next sample while filling a batch. Samples
 * arrive every 10 ms, so this only expires when the stream itself has stalled.
 */
#define ACCEL_FILL_TIMEOUT_MS 15

#define BLE_TX_STACK_SIZE 1024
#define BLE_TX_PRIORITY   7

static struct bt_conn *default_conn;
static atomic_t accel_notify_on;
static atomic_t temp_notify_on;
static atomic_t button_notify_on;

static void accel_ccc_changed(const struct bt_gatt_attr *attr, uint16_t value)
{
	ARG_UNUSED(attr);
	atomic_set(&accel_notify_on, value == BT_GATT_CCC_NOTIFY);

	/* Report the MTU here rather than on connect: the central negotiates it
	 * moments after connecting, so by subscribe time it has settled, and it is
	 * what decides how many samples fit in each notification.
	 */
	if (value == BT_GATT_CCC_NOTIFY && default_conn != NULL) {
		LOG_INF("accel notifications on, ATT MTU %u", bt_gatt_get_mtu(default_conn));
	} else {
		LOG_INF("accel notifications off");
	}
}

static void temp_ccc_changed(const struct bt_gatt_attr *attr, uint16_t value)
{
	ARG_UNUSED(attr);
	atomic_set(&temp_notify_on, value == BT_GATT_CCC_NOTIFY);
	LOG_INF("temperature notifications %s", value == BT_GATT_CCC_NOTIFY ? "on" : "off");
}

static void button_ccc_changed(const struct bt_gatt_attr *attr, uint16_t value)
{
	ARG_UNUSED(attr);
	atomic_set(&button_notify_on, value == BT_GATT_CCC_NOTIFY);
	LOG_INF("button notifications %s", value == BT_GATT_CCC_NOTIFY ? "on" : "off");
}

BT_GATT_SERVICE_DEFINE(mb_svc, BT_GATT_PRIMARY_SERVICE(&uuid_service),

		       BT_GATT_CHARACTERISTIC(&uuid_accel.uuid, BT_GATT_CHRC_NOTIFY,
					      BT_GATT_PERM_NONE, NULL, NULL, NULL),
		       BT_GATT_CCC(accel_ccc_changed, BT_GATT_PERM_READ | BT_GATT_PERM_WRITE),

		       BT_GATT_CHARACTERISTIC(&uuid_temp.uuid, BT_GATT_CHRC_NOTIFY,
					      BT_GATT_PERM_NONE, NULL, NULL, NULL),
		       BT_GATT_CCC(temp_ccc_changed, BT_GATT_PERM_READ | BT_GATT_PERM_WRITE),

		       BT_GATT_CHARACTERISTIC(&uuid_button.uuid, BT_GATT_CHRC_NOTIFY,
					      BT_GATT_PERM_NONE, NULL, NULL, NULL),
		       BT_GATT_CCC(button_ccc_changed, BT_GATT_PERM_READ | BT_GATT_PERM_WRITE), );

/* Value attributes sit one past their characteristic declaration. */
#define ATTR_ACCEL  (&mb_svc.attrs[2])
#define ATTR_TEMP   (&mb_svc.attrs[5])
#define ATTR_BUTTON (&mb_svc.attrs[8])

static const struct bt_data ad[] = {
	BT_DATA_BYTES(BT_DATA_FLAGS, (BT_LE_AD_GENERAL | BT_LE_AD_NO_BREDR)),
	BT_DATA(BT_DATA_NAME_COMPLETE, CONFIG_BT_DEVICE_NAME, sizeof(CONFIG_BT_DEVICE_NAME) - 1),
};

static const struct bt_data sd[] = {
	BT_DATA_BYTES(BT_DATA_UUID128_ALL, UUID_SERVICE_VAL),
};

static void connected(struct bt_conn *conn, uint8_t err)
{
	if (err) {
		LOG_ERR("connection failed (0x%02x)", err);
		return;
	}

	default_conn = bt_conn_ref(conn);
	LOG_INF("connected");

	/* Deliberately no bt_gatt_exchange_mtu() here. Initiating the exchange from
	 * the peripheral looks like a way to avoid depending on the central asking,
	 * but it kills the link against BlueZ: the request draws no response, and
	 * 30 s later the ATT transaction times out and takes the connection with it
	 * (observed as "MTU exchange failed (0x0e)" then disconnect reason 0x16).
	 * Centrals negotiate the MTU themselves on connect, so just use what they
	 * agree to -- CONFIG_BT_L2CAP_TX_MTU sets our side of that ceiling.
	 */
}

static void disconnected(struct bt_conn *conn, uint8_t reason)
{
	ARG_UNUSED(conn);
	LOG_INF("disconnected (0x%02x)", reason);

	atomic_set(&accel_notify_on, 0);
	atomic_set(&temp_notify_on, 0);
	atomic_set(&button_notify_on, 0);

	if (default_conn) {
		bt_conn_unref(default_conn);
		default_conn = NULL;
	}
}

static int advertise(void)
{
	return bt_le_adv_start(BT_LE_ADV_CONN_FAST_1, ad, ARRAY_SIZE(ad), sd, ARRAY_SIZE(sd));
}

/* Restart from `recycled` rather than `disconnected`: by the time this runs the
 * connection object has been freed, so advertising cannot fail with -ENOMEM.
 */
static void recycled(void)
{
	int err = advertise();

	if (err) {
		LOG_ERR("could not resume advertising (%d)", err);
	}
}

BT_CONN_CB_DEFINE(conn_callbacks) = {
	.connected = connected,
	.disconnected = disconnected,
	.recycled = recycled,
};

/* Samples that fit in one notification on the given link. */
static uint8_t accel_batch_size(struct bt_conn *conn)
{
	uint16_t mtu = bt_gatt_get_mtu(conn);
	uint16_t payload;

	if (mtu <= 3 + ACCEL_HDR_LEN + ACCEL_SAMPLE_LEN) {
		return 1;
	}

	payload = mtu - 3;
	return (uint8_t)MIN((payload - ACCEL_HDR_LEN) / ACCEL_SAMPLE_LEN, ACCEL_MAX_BATCH);
}

static void ble_tx_thread(void *p1, void *p2, void *p3)
{
	uint8_t buf[ACCEL_HDR_LEN + ACCEL_MAX_BATCH * ACCEL_SAMPLE_LEN];

	ARG_UNUSED(p1);
	ARG_UNUSED(p2);
	ARG_UNUSED(p3);

	for (;;) {
		struct accel_sample sample;
		struct bt_conn *conn;
		uint8_t want;
		uint8_t count = 0;
		size_t len = ACCEL_HDR_LEN;
		int err;

		if (default_conn == NULL || !atomic_get(&accel_notify_on)) {
			k_sleep(K_MSEC(100));
			continue;
		}

		/* Block for the first sample of the batch, then keep taking until
		 * the batch is full or the stream goes quiet.
		 */
		if (k_msgq_get(&accel_msgq, &sample, K_MSEC(200)) != 0) {
			continue;
		}

		/* Re-read after the wait: the peer may have gone away while we were
		 * blocked, and both calls below would dereference the pointer.
		 */
		conn = default_conn;
		if (conn == NULL) {
			continue;
		}

		want = accel_batch_size(conn);
		sys_put_le32(sample.t_ms, &buf[0]);

		for (;;) {
			sys_put_le16((uint16_t)sample.x, &buf[len]);
			sys_put_le16((uint16_t)sample.y, &buf[len + 2]);
			sys_put_le16((uint16_t)sample.z, &buf[len + 4]);
			len += ACCEL_SAMPLE_LEN;
			count++;

			if (count >= want) {
				break;
			}
			if (k_msgq_get(&accel_msgq, &sample, K_MSEC(ACCEL_FILL_TIMEOUT_MS)) != 0) {
				break;
			}
		}

		buf[4] = count;

		err = bt_gatt_notify(conn, ATTR_ACCEL, buf, len);
		if (err == -ENOMEM) {
			/* Controller buffers are full; let them drain. */
			k_sleep(K_MSEC(5));
		} else if (err) {
			LOG_WRN("accel notify failed (%d)", err);
			k_sleep(K_MSEC(50));
		}
	}
}

K_THREAD_DEFINE(ble_tx_tid, BLE_TX_STACK_SIZE, ble_tx_thread, NULL, NULL, NULL, BLE_TX_PRIORITY, 0,
		0);

void ble_notify_temp(int16_t centi_c)
{
	struct bt_conn *conn = default_conn;
	uint8_t buf[2];
	int err;

	if (conn == NULL || !atomic_get(&temp_notify_on)) {
		return;
	}

	sys_put_le16((uint16_t)centi_c, buf);

	err = bt_gatt_notify(conn, ATTR_TEMP, buf, sizeof(buf));
	if (err) {
		LOG_WRN("temperature notify failed (%d)", err);
	}
}

void ble_notify_button(uint8_t button, uint8_t pressed, uint32_t t_ms)
{
	struct bt_conn *conn = default_conn;
	uint8_t buf[6];
	int err;

	if (conn == NULL || !atomic_get(&button_notify_on)) {
		return;
	}

	buf[0] = button;
	buf[1] = pressed;
	sys_put_le32(t_ms, &buf[2]);

	err = bt_gatt_notify(conn, ATTR_BUTTON, buf, sizeof(buf));
	if (err) {
		LOG_WRN("button notify failed (%d)", err);
	}
}

int ble_start(void)
{
	int err;

	err = bt_enable(NULL);
	if (err) {
		LOG_ERR("bt_enable failed (%d)", err);
		return err;
	}

	err = advertise();
	if (err) {
		LOG_ERR("advertising failed to start (%d)", err);
		return err;
	}

	LOG_INF("advertising as \"%s\"", CONFIG_BT_DEVICE_NAME);
	return 0;
}
```

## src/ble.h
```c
#ifndef APP_BLE_H_
#define APP_BLE_H_

#include <stdint.h>

/** Bring up the stack, register the GATT service, and start advertising. */
int ble_start(void);

/** Queue a temperature reading, in hundredths of a degree Celsius. */
void ble_notify_temp(int16_t centi_c);

/** Queue a button event. @p button is 0 for A and 1 for B; @p pressed is 1/0. */
void ble_notify_button(uint8_t button, uint8_t pressed, uint32_t t_ms);

#endif /* APP_BLE_H_ */
```

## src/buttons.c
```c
/*
 * Both buttons report press and release over BLE. Beyond that they diverge:
 * B buzzes, A starts an audio capture.
 *
 * A must never buzz. The speaker sits centimetres from the microphone on the
 * same board, so a tone on A would be measured by A's own FFT. For the same
 * reason B's buzz is suppressed while a capture is running.
 */

#include "buttons.h"
#include "audio.h"
#include "ble.h"

#include <zephyr/device.h>
#include <zephyr/drivers/buzzer.h>
#include <zephyr/input/input.h>
#include <zephyr/kernel.h>
#include <zephyr/logging/log.h>

LOG_MODULE_REGISTER(buttons, LOG_LEVEL_DBG);

#define BUZZ_FREQ_HZ     440
#define BUZZ_DURATION_MS 80

#define BUTTON_A 0
#define BUTTON_B 1

static const struct device *const buzzer = DEVICE_DT_GET(DT_NODELABEL(buzzer));

static void button_handler(struct input_event *evt, void *user_data)
{
	uint8_t button;
	bool pressed = (evt->value != 0);

	ARG_UNUSED(user_data);

	if (evt->type != INPUT_EV_KEY) {
		return;
	}

	switch (evt->code) {
	case INPUT_KEY_A:
		button = BUTTON_A;
		break;
	case INPUT_KEY_B:
		button = BUTTON_B;
		break;
	default:
		return;
	}

	LOG_DBG("button %c %s", button == BUTTON_A ? 'A' : 'B', pressed ? "press" : "release");
	ble_notify_button(button, pressed ? 1 : 0, k_uptime_get_32());

	if (!pressed) {
		return;
	}

	if (button == BUTTON_A) {
		audio_request_capture();
	} else if (!audio_capture_active()) {
		int err = buzzer_tone(buzzer, BUZZ_FREQ_HZ, BUZZ_DURATION_MS);

		if (err) {
			LOG_WRN("buzzer failed (%d)", err);
		}
	}
}

INPUT_CALLBACK_DEFINE(NULL, button_handler, NULL);

int buttons_init(void)
{
	if (!device_is_ready(buzzer)) {
		LOG_ERR("buzzer not ready");
		return -ENODEV;
	}

	return 0;
}
```

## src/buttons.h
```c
#ifndef APP_BUTTONS_H_
#define APP_BUTTONS_H_

/** Check the buzzer device. The input callback is registered at build time. */
int buttons_init(void);

#endif /* APP_BUTTONS_H_ */
```

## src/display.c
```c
/*
 * Thin wrapper over Zephyr's mb_display, which sits on top of the
 * nordic,nrf-led-matrix driver. All of its calls are asynchronous: they hand
 * the work to a background queue and a new call cancels the one in flight.
 */

#include "display.h"

#include <zephyr/display/mb_display.h>
#include <zephyr/logging/log.h>

LOG_MODULE_REGISTER(display, LOG_LEVEL_INF);

/* Milliseconds per character while scrolling. */
#define SCROLL_MS 300

static struct mb_display *disp;

int display_init(void)
{
	disp = mb_display_get();
	if (disp == NULL) {
		LOG_ERR("LED matrix display unavailable");
		return -ENODEV;
	}

	return 0;
}

void display_frequency(uint32_t hz)
{
	if (disp == NULL) {
		return;
	}

	mb_display_print(disp, MB_DISPLAY_MODE_SCROLL, SCROLL_MS, "%u", hz);
}

void display_text(const char *text)
{
	if (disp == NULL) {
		return;
	}

	mb_display_print(disp, MB_DISPLAY_MODE_SCROLL, SCROLL_MS, "%s", text);
}
```

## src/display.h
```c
#ifndef APP_DISPLAY_H_
#define APP_DISPLAY_H_

#include <stdint.h>

int display_init(void);

/** Scroll a frequency in Hz across the 5x5 matrix. */
void display_frequency(uint32_t hz);

/** Scroll a short string. Calls are asynchronous and cancel any previous one. */
void display_text(const char *text);

#endif /* APP_DISPLAY_H_ */
```

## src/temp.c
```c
/*
 * The nRF52833's on-die temperature sensor, sampled once a second. This is the
 * CPU die, not the room -- the micro:bit V2 has no ambient sensor -- so expect
 * readings a few degrees above room temperature.
 *
 * The peripheral is shared: because the board clocks its LF domain from the
 * internal RC oscillator, Zephyr's clock calibration samples it too. That is
 * safe, since temp_nrf5.c guards each conversion with a mutex.
 */

#include "temp.h"
#include "ble.h"

#include <stdlib.h>

#include <zephyr/device.h>
#include <zephyr/drivers/sensor.h>
#include <zephyr/kernel.h>
#include <zephyr/logging/log.h>

LOG_MODULE_REGISTER(temp, LOG_LEVEL_DBG);

#define TEMP_PERIOD_MS  1000
#define TEMP_STACK_SIZE 768
#define TEMP_PRIORITY   8

static const struct device *const temp_dev = DEVICE_DT_GET_ANY(nordic_nrf_temp);

static void temp_thread(void *p1, void *p2, void *p3)
{
	ARG_UNUSED(p1);
	ARG_UNUSED(p2);
	ARG_UNUSED(p3);

	for (;;) {
		struct sensor_value val;
		int16_t centi_c;
		int err;

		k_sleep(K_MSEC(TEMP_PERIOD_MS));

		err = sensor_sample_fetch_chan(temp_dev, SENSOR_CHAN_DIE_TEMP);
		if (err) {
			LOG_ERR("fetch failed (%d)", err);
			continue;
		}

		err = sensor_channel_get(temp_dev, SENSOR_CHAN_DIE_TEMP, &val);
		if (err) {
			LOG_ERR("channel get failed (%d)", err);
			continue;
		}

		centi_c = (int16_t)(sensor_value_to_milli(&val) / 10);
		LOG_DBG("die temperature %d.%02d C", centi_c / 100, abs(centi_c % 100));

		ble_notify_temp(centi_c);
	}
}

K_THREAD_DEFINE(temp_tid, TEMP_STACK_SIZE, temp_thread, NULL, NULL, NULL, TEMP_PRIORITY, 0,
		K_TICKS_FOREVER);

int temp_start(void)
{
	if (!device_is_ready(temp_dev)) {
		LOG_ERR("die temperature sensor not ready");
		return -ENODEV;
	}

	k_thread_start(temp_tid);
	LOG_INF("die temperature sampling at 1 Hz");
	return 0;
}
```

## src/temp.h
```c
#ifndef APP_TEMP_H_
#define APP_TEMP_H_

/** Start the 1 Hz die-temperature poll. */
int temp_start(void);

#endif /* APP_TEMP_H_ */
```
